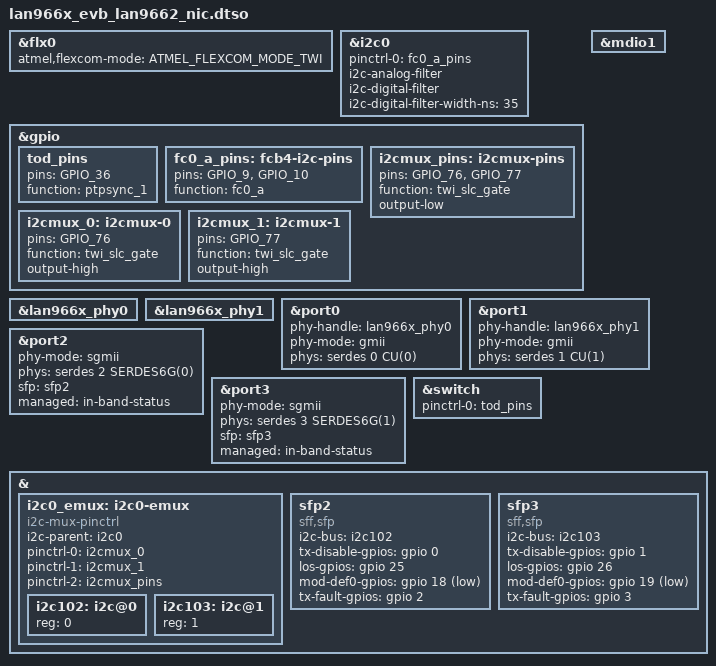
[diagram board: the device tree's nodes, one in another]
// SPDX-License-Identifier: GPL-2.0
/*
 * Copyright (C) 2022 Microchip UNG
 */

#include <dt-bindings/gpio/gpio.h>
#include <dt-bindings/mfd/atmel-flexcom.h>
#include <dt-bindings/phy/phy-lan966x-serdes.h>

/dts-v1/;
/plugin/;

/ {
	fragment@0 {
		target-path = "";

		/*
		 * These properties allow to avoid a dtc warnings.
		 * The real interrupt controller is the PCI device itself. It
		 * is the node on which the device tree overlay will be applied.
		 * This node has those properties.
		 */
		#interrupt-cells = <1>;
		interrupt-controller;

		__overlay__ {
			#address-cells = <3>;
			#size-cells = <2>;

			#include "lan966x_pci.dtsi"

			i2c0_emux: i2c0-emux {
				compatible = "i2c-mux-pinctrl";
				#address-cells = <1>;
				#size-cells = <0>;
				i2c-parent = <&i2c0>;
				pinctrl-names = "i2c102", "i2c103", "idle";
				pinctrl-0 = <&i2cmux_0>;
				pinctrl-1 = <&i2cmux_1>;
				pinctrl-2 = <&i2cmux_pins>;

				i2c102: i2c@0 {
					reg = <0>;
					#address-cells = <1>;
					#size-cells = <0>;
				};

				i2c103: i2c@1 {
					reg = <1>;
					#address-cells = <1>;
					#size-cells = <0>;
				};
			};

			sfp2: sfp2 {
				compatible = "sff,sfp";
				i2c-bus = <&i2c102>;
				tx-disable-gpios = <&gpio 0 GPIO_ACTIVE_HIGH>;
				los-gpios = <&gpio 25 GPIO_ACTIVE_HIGH>;
				mod-def0-gpios = <&gpio 18 GPIO_ACTIVE_LOW>;
				tx-fault-gpios = <&gpio 2 GPIO_ACTIVE_HIGH>;
			};

			sfp3: sfp3 {
				compatible = "sff,sfp";
				i2c-bus = <&i2c103>;
				tx-disable-gpios = <&gpio 1 GPIO_ACTIVE_HIGH>;
				los-gpios = <&gpio 26 GPIO_ACTIVE_HIGH>;
				mod-def0-gpios = <&gpio 19 GPIO_ACTIVE_LOW>;
				tx-fault-gpios = <&gpio 3 GPIO_ACTIVE_HIGH>;
			};
		};
	};
};

&flx0 {
	atmel,flexcom-mode = <ATMEL_FLEXCOM_MODE_TWI>;
	status = "okay";
};

&i2c0 {
	pinctrl-0 = <&fc0_a_pins>;
	pinctrl-names = "default";
	i2c-analog-filter;
	i2c-digital-filter;
	i2c-digital-filter-width-ns = <35>;
	status = "okay";
};

&gpio {
	tod_pins: tod_pins {
		pins = "GPIO_36";
		function = "ptpsync_1";
	};

	fc0_a_pins: fcb4-i2c-pins {
		/* RXD, TXD */
		pins = "GPIO_9", "GPIO_10";
		function = "fc0_a";
	};

	i2cmux_pins: i2cmux-pins {
		pins = "GPIO_76", "GPIO_77";
		function = "twi_slc_gate";
		output-low;
	};

	i2cmux_0: i2cmux-0 {
		pins = "GPIO_76";
		function = "twi_slc_gate";
		output-high;
	};

	i2cmux_1: i2cmux-1 {
		pins = "GPIO_77";
		function = "twi_slc_gate";
		output-high;
	};
};

&lan966x_phy0 {
	status = "okay";
};

&lan966x_phy1 {
	status = "okay";
};

&mdio1 {
	status = "okay";
};

&port0 {
	phy-handle = <&lan966x_phy0>;
	phy-mode = "gmii";
	phys = <&serdes 0 CU(0)>;
	status = "okay";
};

&port1 {
	phy-handle = <&lan966x_phy1>;
	phy-mode = "gmii";
	phys = <&serdes 1 CU(1)>;
	status = "okay";
};

&port2 {
	phy-mode = "sgmii";
	phys = <&serdes 2 SERDES6G(0)>;
	sfp = <&sfp2>;
	managed = "in-band-status";
	status = "okay";
};

&port3 {
	phy-mode = "sgmii";
	phys = <&serdes 3 SERDES6G(1)>;
	sfp = <&sfp3>;
	managed = "in-band-status";
	status = "okay";
};

&switch {
	pinctrl-names = "default";
	pinctrl-0 = <&tod_pins>;
	status = "okay";
};
